# STM32U385 register map
File version: 1.0
CPU: CM33 r0p1, little endian, MPU, FPU, 4 interrupt priority bits
Registers are 32-bit, read-write, reset 0x0 unless marked. A register's access mark holds for its fields unless they carry their own. Offsets are from the block's base; [hi:lo] are bit positions; {n}, {i} and the like mark numbered series; 'fields as' and 'values as' point back to an identical list.

## DAC — DAC Address block
Base 0x42028400
Same registers: SEC_DAC 0x52028400
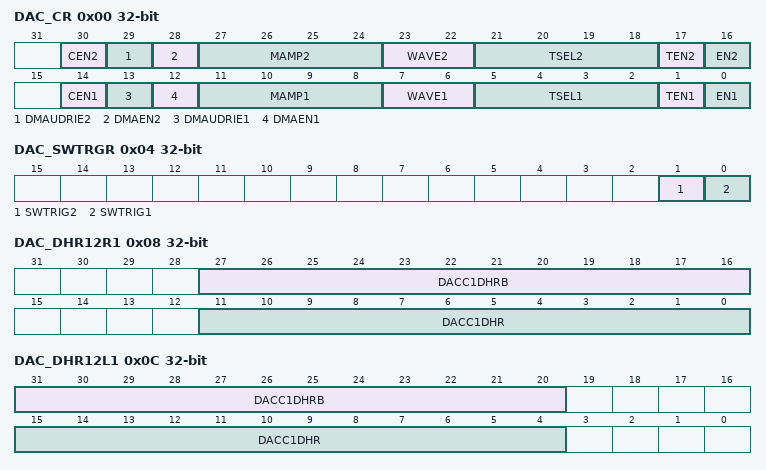
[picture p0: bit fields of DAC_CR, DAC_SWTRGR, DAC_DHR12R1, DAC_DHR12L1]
0x00 DAC_CR — DAC control register
  [30] CEN2 — This bit is set and cleared by software to enable/disable DAC channel2 calibration, it can be written only if EN2 bit is set to 0 into DAC_CR (the calibration mode can be entered/exit only when the DAC channel is disabled) Otherwise, the write operation is ignored. 0: DAC channel2 in Normal operating mode 1: DAC channel2 in calibration mode Note: This bit is available only on dual-channel DACs. Refer to less than xe1 [Implementation]/>.
    0=DAC channel2 in Normal operating mode; 1=DAC channel2 in calibration mode
  [29] DMAUDRIE2 — This bit is set and cleared by software. 0: DAC channel2 DMA underrun interrupt disabled 1: DAC channel2 DMA underrun interrupt enabled Note: This bit is available only on dual-channel DACs. Refer to less than xe1 [Implementation]/>.
    0=DAC channel2 DMA underrun interrupt disabled; 1=DAC channel2 DMA underrun interrupt enabled
  [28] DMAEN2 — This bit is set and cleared by software. 0: DAC channel2 DMA mode disabled 1: DAC channel2 DMA mode enabled Note: This bit is available only on dual-channel DACs. Refer to less than xe1 [Implementation]/>.
    0=DAC channel2 DMA mode disabled; 1=DAC channel2 DMA mode enabled
  [27:24] MAMP2 — These bits are written by software to select mask in wave generation mode or amplitude in triangle generation mode. 0000: Unmask bit0 of LFSR/ triangle amplitude equal to 1 0001: Unmask bits[1:0] of LFSR/ triangle amplitude equal to 3 0010: Unmask bits[2:0] of LFSR/ triangle amplitude equal to 7 0011: Unmask bits[3:0] of LFSR/ triangle amplitude equal to 15 0100: Unmask bits[4:0] of LFSR/ triangle amplitude equal to 31 0101: Unmask bits[5:0] of LFSR/ triangle amplitude equal to 63 0110: Unmask bits[6:0] of LFSR/ triangle amplitude equal to 127 0111: Unmask bits[7:0] of LFSR/ triangle amplitude equal to 255 1000: Unmask bits[8:0] of LFSR/ triangle amplitude equal to 511 1001: Unmask bits[9:0] of LFSR/ triangle amplitude equal to 1023 1010: Unmask bits[10:0] of LFSR/ triangle amplitude equal to 2047 Others: Unmask bits[11:0] of LFSR/ triangle amplitude equal to 4095 Note: These bits are available only on dual-channel DACs. Refer to less than xe1 [Implementation]/>.
    0=Unmask bit0 of LFSR/ triangle amplitude equal to 1; 1=Unmask bits[1:0] of LFSR/ triangle amplitude equal to 3; 2=Unmask bits[2:0] of LFSR/ triangle amplitude equal to 7; 3=Unmask bits[3:0] of LFSR/ triangle amplitude equal to 15; 4=Unmask bits[4:0] of LFSR/ triangle amplitude equal to 31; 5=Unmask bits[5:0] of LFSR/ triangle amplitude equal to 63; 6=Unmask bits[6:0] of LFSR/ triangle amplitude equal to 127; 7=Unmask bits[7:0] of LFSR/ triangle amplitude equal to 255; 8=Unmask bits[8:0] of LFSR/ triangle amplitude equal to 511; 9=Unmask bits[9:0] of LFSR/ triangle amplitude equal to 1023; 10=Unmask bits[10:0] of LFSR/ triangle amplitude equal to 2047
  [23:22] WAVE2 — These bits are set/reset by software. 00: wave generation disabled 01: Noise wave generation enabled 10: Triangle wave generation enabled 11: Triangle wave generation enabled Note: Only used if bit TEN2 = 1 (DAC channel2 trigger enabled) Note: These bits are available only on dual-channel DACs. Refer to less than xe1 [Implementation]/>.
    0=wave generation disabled; 1=Noise wave generation enabled; 2=Triangle wave generation enabled; 3=Triangle wave generation enabled
  [21:18] TSEL2 — These bits select the external event used to trigger DAC channel2 Refer to the trigger selection tables in less than xe2 [dacif2_TrigSel]/> for details on trigger configuration and mapping. 0000: SWTRIG2 0001-1111: dac_ch2_trg{val} Note: Only used if bit TEN2 = 1 (DAC channel2 trigger enabled). These bits are available only on dual-channel DACs. Refer to less than xe1 [Implementation]/>.
    0=SWTRIG2; {v}=dac_ch2_trg{v} (v=1..15)
  [17] TEN2 — This bit is set and cleared by software to enable/disable DAC channel2 trigger. 0: DAC channel2 trigger disabled and data written into the DAC_DHR2 register are transferred one dac_pclk clock cycle later to the DAC_DOR2 register 1: DAC channel2 trigger enabled and data from the DAC_DHR2 register are transferred three dac_pclk clock cycles later to the DAC_DOR2 register Note: When software trigger is selected, the transfer from the DAC_DHR2 register to the DAC_DOR2 register takes only one dac_pclk clock cycle. These bits are available only on dual-channel DACs. Refer to less than xe1 [Implementation]/>.
    0=DAC channel2 trigger disabled and data written into the DAC_DHR2 register are transferred one dac_pclk clock cycle later to the DAC_DOR2 register; 1=DAC channel2 trigger enabled and data from the DAC_DHR2 register are transferred three dac_pclk clock cycles later to the DAC_DOR2 register
  [16] EN2 — This bit is set and cleared by software to enable/disable DAC channel2. 0: DAC channel2 disabled 1: DAC channel2 enabledSection 19.3: DAC implementation Note: These bits are available only on dual-channel DACs. Refer to less than xe1 [Implementation]/>.
    0=DAC channel2 disabled; 1=DAC channel2 enabledSection 19.3: DAC implementation
  [14] CEN1 — This bit is set and cleared by software to enable/disable DAC channel1 calibration, it can be written only if bit EN1 = 0 into DAC_CR (the calibration mode can be entered/exit only when the DAC channel is disabled) Otherwise, the write operation is ignored. 0: DAC channel1 in Normal operating mode 1: DAC channel1 in calibration mode
    0=DAC channel1 in Normal operating mode; 1=DAC channel1 in calibration mode
  [13] DMAUDRIE1 — This bit is set and cleared by software. 0: DAC channel1 DMA Underrun Interrupt disabled 1: DAC channel1 DMA Underrun Interrupt enabled
    0=DAC channel1 DMA Underrun Interrupt disabled; 1=DAC channel1 DMA Underrun Interrupt enabled
  [12] DMAEN1 — This bit is set and cleared by software. 0: DAC channel1 DMA mode disabled 1: DAC channel1 DMA mode enabled
    0=DAC channel1 DMA mode disabled; 1=DAC channel1 DMA mode enabled
  [11:8] MAMP1 — These bits are written by software to select mask in wave generation mode or amplitude in triangle generation mode. 0000: Unmask bit0 of LFSR/ triangle amplitude equal to 1 0001: Unmask bits[1:0] of LFSR/ triangle amplitude equal to 3 0010: Unmask bits[2:0] of LFSR/ triangle amplitude equal to 7 0011: Unmask bits[3:0] of LFSR/ triangle amplitude equal to 15 0100: Unmask bits[4:0] of LFSR/ triangle amplitude equal to 31 0101: Unmask bits[5:0] of LFSR/ triangle amplitude equal to 63 0110: Unmask bits[6:0] of LFSR/ triangle amplitude equal to 127 0111: Unmask bits[7:0] of LFSR/ triangle amplitude equal to 255 1000: Unmask bits[8:0] of LFSR/ triangle amplitude equal to 511 1001: Unmask bits[9:0] of LFSR/ triangle amplitude equal to 1023 1010: Unmask bits[10:0] of LFSR/ triangle amplitude equal to 2047 Others: Unmask bits[11:0] of LFSR/ triangle amplitude equal to 4095
    values as MAMP2
  [7:6] WAVE1 — None 00: wave generation disabled 01: Noise wave generation enabled 10: Triangle wave generation enabled 11: Triangle wave generation enabled Note: Only used if bit TEN1 = 1 (DAC channel1 trigger enabled). Refer to less than xe1 [Implementation]/>.
    values as WAVE2
  [5:2] TSEL1 — These bits select the external event used to trigger DAC channel2 Refer to the trigger selection tables in less than xe2 [dacif2_TrigSel]/> for details on trigger configuration and mapping. 0000: SWTRIG1 0001-1111: dac_ch1_trg{val} Note: Only used if bit TEN1 = 1 (DAC channel1 trigger enabled). Note: These bits are available only on dual-channel DACs. Refer to less than xe1 [Implementation]/>
    0=SWTRIG1; {v}=dac_ch1_trg{v} (v=1..15)
  [1] TEN1 — This bit is set and cleared by software to enable/disable DAC channel1 trigger. 0: DAC channel1 trigger disabled and data written into the DAC_DHR1 register are transferred one dac_pclk clock cycle later to the DAC_DOR1 register 1: DAC channel1 trigger enabled and data from the DAC_DHR1 register are transferred three dac_pclk clock cycles later to the DAC_DOR1 register Note: When software trigger is selected, the transfer from the DAC_DHR1 register to the DAC_DOR1 register takes only one dac_pclk clock cycle.
    0=DAC channel1 trigger disabled and data written into the DAC_DHR1 register are transferred one dac_pclk clock cycle later to the DAC_DOR1 register; 1=DAC channel1 trigger enabled and data from the DAC_DHR1 register are transferred three dac_pclk clock cycles later to the DAC_DOR1 register
  [0] EN1 — This bit is set and cleared by software to enable/disable DAC channel1. 0: DAC channel1 disabled 1: DAC channel1 enabled
    0=DAC channel1 disabled; 1=DAC channel1 enabled
0x04 DAC_SWTRGR wo — DAC software trigger register
  [1] SWTRIG2 — This bit is set by software to trigger the DAC in software trigger mode. 0: No trigger 1: Trigger Note: This bit is cleared by hardware (one dac_pclk clock cycle later) once the DAC_DHR2 register value has been loaded into the DAC_DOR2 register. Note: This bit is available only on dual-channel DACs. Refer to less than xe1 [Implementation]/>.
    0=No trigger; 1=Trigger
  [0] SWTRIG1 — This bit is set by software to trigger the DAC in software trigger mode. 0: No trigger 1: Trigger Note: This bit is cleared by hardware (one dac_pclk clock cycle later) once the DAC_DHR1 register value has been loaded into the DAC_DOR1 register.
    0=No trigger; 1=Trigger
0x08 DAC_DHR12R1 — DAC channel1 12-bit right-aligned data holding register
  [27:16] DACC1DHRB — These bits are written by software. They specify 12-bit data for DAC channel1 when the DAC operates in Double data mode.
  [11:0] DACC1DHR — These bits are written by software. They specify 12-bit data for DAC channel1.
0x0C DAC_DHR12L1 — DAC channel1 12-bit left aligned data holding register
  [31:20] DACC1DHRB — These bits are written by software. They specify 12-bit data for DAC channel1 when the DAC operates in Double data mode.
  [15:4] DACC1DHR — These bits are written by software. They specify 12-bit data for DAC channel1.
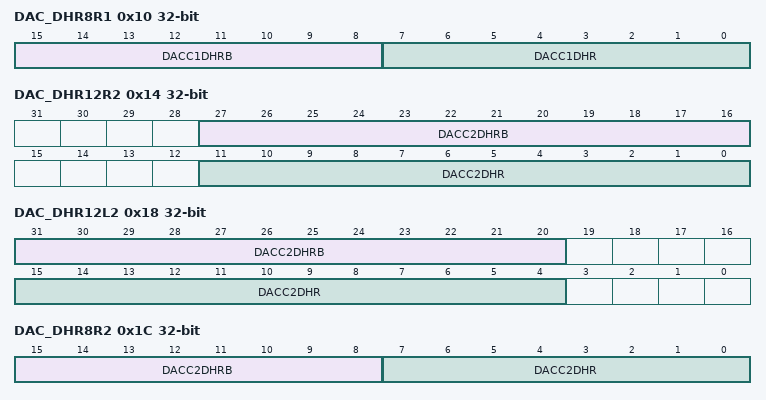
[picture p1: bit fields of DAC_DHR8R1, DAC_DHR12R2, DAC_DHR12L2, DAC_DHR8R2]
0x10 DAC_DHR8R1 — DAC channel1 8-bit right aligned data holding register
  [15:8] DACC1DHRB — These bits are written by software. They specify 8-bit data for DAC channel1 when the DAC operates in Double data mode.
  [7:0] DACC1DHR — These bits are written by software. They specify 8-bit data for DAC channel1.
0x14 DAC_DHR12R2 — DAC channel2 12-bit right aligned data holding register
  [27:16] DACC2DHRB — These bits are written by software. They specify 12-bit data for DAC channel2 when the DAC operates in DMA Double data mode.
  [11:0] DACC2DHR — These bits are written by software. They specify 12-bit data for DAC channel2.
0x18 DAC_DHR12L2 — DAC channel2 12-bit left aligned data holding register
  [31:20] DACC2DHRB — These bits are written by software. They specify 12-bit data for DAC channel2 when the DAC operates in Double data mode.
  [15:4] DACC2DHR — These bits are written by software which specify 12-bit data for DAC channel2.
0x1C DAC_DHR8R2 — DAC channel2 8-bit right-aligned data holding register
  [15:8] DACC2DHRB — These bits are written by software. They specify 8-bit data for DAC channel2 when the DAC operates in Double data mode.
  [7:0] DACC2DHR — These bits are written by software which specifies 8-bit data for DAC channel2.
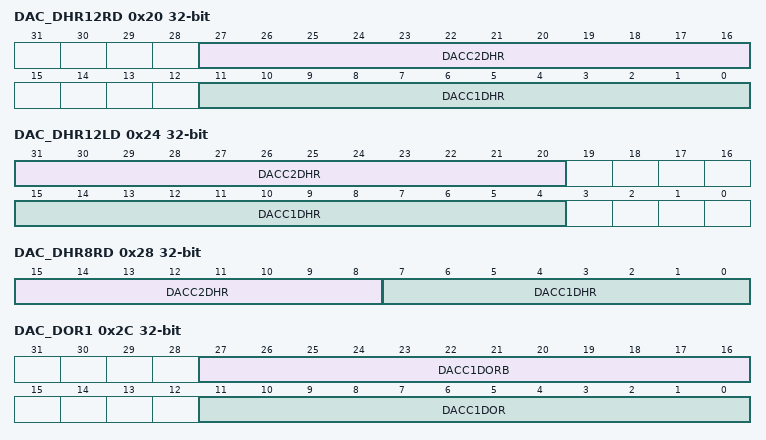
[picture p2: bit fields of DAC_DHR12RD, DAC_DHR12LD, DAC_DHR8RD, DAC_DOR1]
0x20 DAC_DHR12RD — Dual DAC 12-bit right-aligned data holding register
  [27:16] DACC2DHR — These bits are written by software which specifies 12-bit data for DAC channel2.
  [11:0] DACC1DHR — These bits are written by software which specifies 12-bit data for DAC channel1.
0x24 DAC_DHR12LD — Dual DAC 12-bit left aligned data holding register
  [31:20] DACC2DHR — These bits are written by software which specifies 12-bit data for DAC channel2.
  [15:4] DACC1DHR — These bits are written by software which specifies 12-bit data for DAC channel1.
0x28 DAC_DHR8RD — Dual DAC 8-bit right aligned data holding register
  [15:8] DACC2DHR — These bits are written by software which specifies 8-bit data for DAC channel2.
  [7:0] DACC1DHR — These bits are written by software which specifies 8-bit data for DAC channel1.
0x2C DAC_DOR1 ro — DAC channel1 data output register
  [27:16] DACC1DORB — These bits are read-only. They contain data output for DAC channel1.
  [11:0] DACC1DOR — These bits are read-only, they contain data output for DAC channel1.
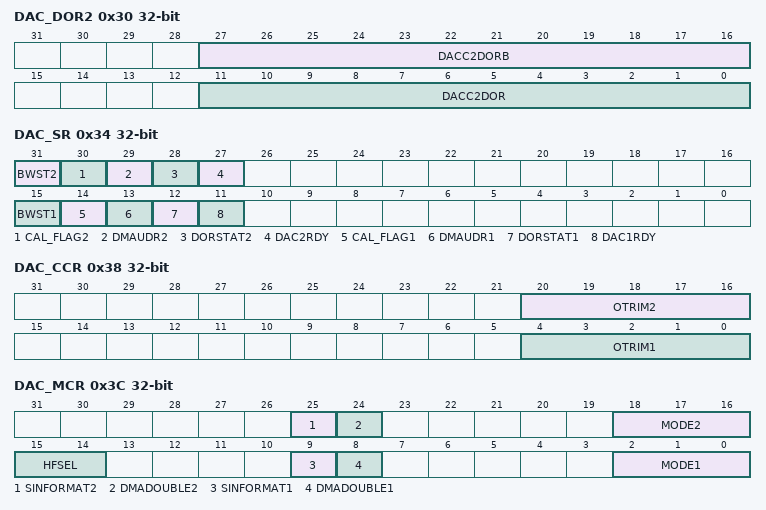
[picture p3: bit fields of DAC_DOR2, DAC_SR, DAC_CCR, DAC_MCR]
0x30 DAC_DOR2 ro — DAC channel2 data output register
  [27:16] DACC2DORB — These bits are read-only. They contain data output for DAC channel2.
  [11:0] DACC2DOR — These bits are read-only, they contain data output for DAC channel2.
0x34 DAC_SR access per field — DAC status register
  [31] BWST2 ro — This bit is systematically set just after Sample and hold mode enable. It is set each time the software writes the register DAC_SHSR2, It is cleared by hardware when the write operation of DAC_SHSR2 is complete. (It takes about 3 LSI/LSE periods of synchronization). 0: There is no write operation of DAC_SHSR2 ongoing: DAC_SHSR2 can be written 1: There is a write operation of DAC_SHSR2 ongoing: DAC_SHSR2 cannot be written Note: This bit is available only on dual-channel DACs. Refer to less than xe1 [Implementation]/>.
    0=There is no write operation of DAC_SHSR2 ongoing: DAC_SHSR2 can be written; 1=There is a write operation of DAC_SHSR2 ongoing: DAC_SHSR2 cannot be written
  [30] CAL_FLAG2 ro — This bit is set and cleared by hardware 0: calibration trimming value is lower than the offset correction value 1: calibration trimming value is equal or greater than the offset correction value Note: This bit is available only on dual-channel DACs. Refer to less than xe1 [Implementation]/>.
    0=calibration trimming value is lower than the offset correction value; 1=calibration trimming value is equal or greater than the offset correction value
  [29] DMAUDR2 rw — This bit is set by hardware and cleared by software (by writing it to 1). 0: No DMA underrun error condition occurred for DAC channel21: DMA underrun error condition occurred for DAC channel2 (the currently selected trigger is driving DAC channel2 conversion at a frequency higher than the DMA service capability rate). Note: This bit is available only on dual-channel DACs. Refer to less than xe1 [Implementation]/>.
    0=No DMA underrun error condition occurred for DAC channel21: DMA underrun error condition occurred for DAC channel2 (the currently selected trigger is driving DAC channel2 conversion at a frequency higher than the DMA service capability rate)
  [28] DORSTAT2 ro — This bit is set and cleared by hardware. It is applicable only when the DAC operates in Double data mode. 0: DOR[11:0] is used actual DAC output 1: DORB[11:0] is used actual DAC outputSection Note: This bit is available only on dual-channel DACs. Refer to less than xe1 [Implementation]/>.
    0=DOR[11:0] is used actual DAC output; 1=DORB[11:0] is used actual DAC outputSection
  [27] DAC2RDY ro — This bit is set and cleared by hardware. 0: DAC channel2 is not yet ready to accept the trigger nor output data 1: DAC channel2 is ready to accept the trigger or output data Note: This bit is available only on dual-channel DACs. Refer to less than xe1 [Implementation]/>.
    0=DAC channel2 is not yet ready to accept the trigger nor output data; 1=DAC channel2 is ready to accept the trigger or output data
  [15] BWST1 ro — None 0: There is no write operation of DAC_SHSR1 ongoing: DAC_SHSR1 can be written 1: There is a write operation of DAC_SHSR1 ongoing: DAC_SHSR1 cannot be written
    0=There is no write operation of DAC_SHSR1 ongoing: DAC_SHSR1 can be written; 1=There is a write operation of DAC_SHSR1 ongoing: DAC_SHSR1 cannot be written
  [14] CAL_FLAG1 ro — None 0: calibration trimming value is lower than the offset correction value 1: calibration trimming value is equal or greater than the offset correction value
    values as CAL_FLAG2
  [13] DMAUDR1 rw — This bit is set by hardware and cleared by software (by writing it to 1). 0: No DMA underrun error condition occurred for DAC channel1 1: DMA underrun error condition occurred for DAC channel1 (the currently selected trigger is driving DAC channel1 conversion at a frequency higher than the DMA service capability rate)
    0=No DMA underrun error condition occurred for DAC channel1; 1=DMA underrun error condition occurred for DAC channel1 (the currently selected trigger is driving DAC channel1 conversion at a frequency higher than the DMA service capability rate)
  [12] DORSTAT1 ro — This bit is set and cleared by hardware. It is applicable only when the DAC operates in Double data mode. 0: DOR[11:0] is used actual DAC output 1: DORB[11:0] is used actual DAC output
    0=DOR[11:0] is used actual DAC output; 1=DORB[11:0] is used actual DAC output
  [11] DAC1RDY ro — This bit is set and cleared by hardware. 0: DAC channel1 is not yet ready to accept the trigger nor output data 1: DAC channel1 is ready to accept the trigger or output data
    0=DAC channel1 is not yet ready to accept the trigger nor output data; 1=DAC channel1 is ready to accept the trigger or output data
0x38 DAC_CCR (reset mask 0xFFE0FFE0) — DAC calibration control register
  [20:16] OTRIM2 — These bits are available only on dual-channel DACs. Refer to less than xe1 [Implementation]/>.
  [4:0] OTRIM1
0x3C DAC_MCR — DAC mode control register
  [25] SINFORMAT2 — This bit is set and cleared by software. 0: Input data is in unsigned format 1: Input data is in signed format (2's complement). The MSB bit represents the sign. Note: This bit is available only on dual-channel DACs. Refer to less than xe1 [Implementation]/>.
    0=Input data is in unsigned format; 1=Input data is in signed format (2's complement). The MSB bit represents the sign.
  [24] DMADOUBLE2 — This bit is set and cleared by software. 0: DMA Normal mode selected 1: DMA Double data mode selected Note: This bit is available only on dual-channel DACs. Refer to less than xe1 [Implementation]/>.
    0=DMA Normal mode selected; 1=DMA Double data mode selected
  [18:16] MODE2 — These bits can be written only when the DAC is disabled and not in the calibration mode (when bit EN2 = 0 and bit CEN2 = 0 in the DAC_CR register). If EN2 = 1 or CEN2 = 1 the write operation is ignored. They can be set and cleared by software to select the DAC channel2 mode. 000: DAC channel2 in Normal mode is connected to external pin with Buffer enabled 001: DAC channel2 in Normal mode is connected to external pin and to on chip peripherals with buffer enabled 010: DAC channel2 in Normal mode is connected to external pin with buffer disabled 011: DAC channel2 in Normal mode is connected to on chip peripherals with Buffer disabled 100: DAC channel2 in Sample and hold mode is connected to external pin with Buffer enabled 101: DAC channel2 in Sample and hold mode is connected to external pin and to on chip peripherals with Buffer enabled 110: DAC channel2 in Sample and hold mode is connected to external pin and to on chip peripherals with Buffer disabled 111: DAC channel2 in Sample and hold mode is connected to on chip peripherals with Buffer disabled Note: This register can be modified only when EN2 = 0. Note: Refer to less than xe1 [Implementation]/> for the availability of DAC channel2.
    0=DAC channel2 in Normal mode is connected to external pin with Buffer enabled; 1=DAC channel2 in Normal mode is connected to external pin and to on chip peripherals with buffer enabled; 2=DAC channel2 in Normal mode is connected to external pin with buffer disabled; 3=DAC channel2 in Normal mode is connected to on chip peripherals with Buffer disabled; 4=DAC channel2 in Sample and hold mode is connected to external pin with Buffer enabled; 5=DAC channel2 in Sample and hold mode is connected to external pin and to on chip peripherals with Buffer enabled; 6=DAC channel2 in Sample and hold mode is connected to external pin and to on chip peripherals with Buffer disabled; 7=DAC channel2 in Sample and hold mode is connected to on chip peripherals with Buffer disabled
  [15:14] HFSEL — None 00: High frequency interface mode disabled 01: High frequency interface mode compatible to AHB greater or equal 48 MHz enabled 10: Reserved 11: Reserved
    0=High frequency interface mode disabled; 1=High frequency interface mode compatible to AHB greater or equal 48 MHz enabled
  [9] SINFORMAT1 — This bit is set and cleared by software. 0: Input data is in unsigned format 1: Input data is in signed format (2's complement). The MSB bit represents the sign.
    values as SINFORMAT2
  [8] DMADOUBLE1 — This bit is set and cleared by software. 0: DMA Normal mode selected 1: DMA Double data mode selected
    0=DMA Normal mode selected; 1=DMA Double data mode selected
  [2:0] MODE1 — These bits can be written only when the DAC is disabled and not in the calibration mode (when bit EN1 = 0 and bit CEN1 = 0 in the DAC_CR register). If EN1 = 1 or CEN1 = 1 the write operation is ignored. They can be set and cleared by software to select the DAC channel1 mode. 000: DAC channel1 in Normal mode is connected to external pin with Buffer enabled 001: DAC channel1 in Normal mode is connected to external pin and to on chip peripherals with buffer enabled 010: DAC channel1 in Normal mode is connected to external pin with buffer disabled 011: DAC channel1 in Normal mode is connected to on chip peripherals with Buffer disabled 100: DAC channel1 in Sample and hold mode is connected to external pin with Buffer enabled 101: DAC channel1 in Sample and hold mode is connected to external pin and to on chip peripherals with Buffer enabled 110: DAC channel1 in Sample and hold mode is connected to external pin and to on chip peripherals with Buffer disabled 111: DAC channel1 in Sample and hold mode is connected to on chip peripherals with Buffer disabled Note: This register can be modified only when EN1 = 0.
    0=DAC channel1 in Normal mode is connected to external pin with Buffer enabled; 1=DAC channel1 in Normal mode is connected to external pin and to on chip peripherals with buffer enabled; 2=DAC channel1 in Normal mode is connected to external pin with buffer disabled; 3=DAC channel1 in Normal mode is connected to on chip peripherals with Buffer disabled; 4=DAC channel1 in Sample and hold mode is connected to external pin with Buffer enabled; 5=DAC channel1 in Sample and hold mode is connected to external pin and to on chip peripherals with Buffer enabled; 6=DAC channel1 in Sample and hold mode is connected to external pin and to on chip peripherals with Buffer disabled; 7=DAC channel1 in Sample and hold mode is connected to on chip peripherals with Buffer disabled
0x40 DAC_SHSR1 — DAC channel1 sample and hold sample time register
  [9:0] TSAMPLE1 — These bits can be written when the DAC channel1 is disabled or also during normal operation. in the latter case, the write can be done only when BWST1 of DAC_SR register is low, If BWST1 = 1, the write operation is ignored.
0x44 DAC_SHSR2 — DAC channel2 sample and hold sample time register
  [9:0] TSAMPLE2 — These bits can be written when the DAC channel2 is disabled or also during normal operation.
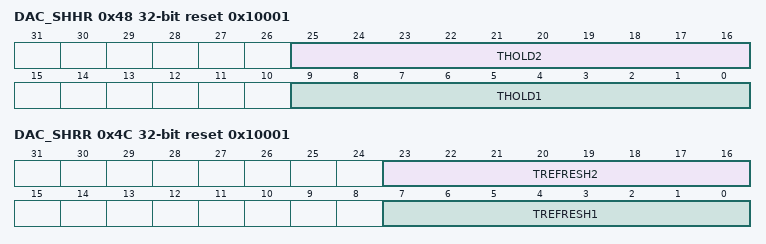
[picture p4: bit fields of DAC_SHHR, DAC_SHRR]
0x48 DAC_SHHR reset 0x10001 — DAC sample and hold time register
  [25:16] THOLD2 — Hold time = (THOLD[9:0]) x LSI/LSE clock period Note: This register can be modified only when EN2 = 0. Note: These bits are available only on dual-channel DACs. Refer to less than xe1 [Implementation]/>.
  [9:0] THOLD1 — Hold time = (THOLD[9:0]) x LSI/LSE clock period Note: This register can be modified only when EN1 = 0.
0x4C DAC_SHRR reset 0x10001 — DAC sample and hold refresh time register
  [23:16] TREFRESH2 — Refresh time = (TREFRESH[7:0]) x LSI / LSE clock period Note: This register can be modified only when EN2 = 0. Note: These bits are available only on dual-channel DACs. Refer to less than xe1 [Implementation]/>.
  [7:0] TREFRESH1 — Refresh time = (TREFRESH[7:0]) x LSI / LSE clock period Note: This register can be modified only when EN1 = 0.
0x54 DAC_AUTOCR — DAC Autonomous mode control register
  [22] AUTOMODE — This bit is set and cleared by software. 0: DAC Autonomous mode disabled 1: DAC Autonomous mode enabled
    0=DAC Autonomous mode disabled; 1=DAC Autonomous mode enabled
